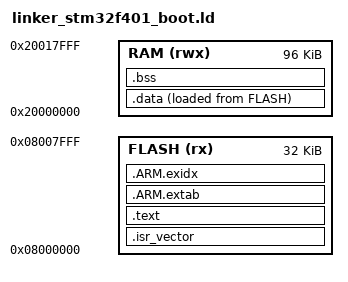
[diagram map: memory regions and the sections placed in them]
ENTRY(Reset_Handler)

MEMORY
{
    FLASH (rx)  : ORIGIN = 0x08000000, LENGTH = 32K
    RAM   (rwx) : ORIGIN = 0x20000000, LENGTH = 96K
}

_estack = ORIGIN(RAM) + LENGTH(RAM);

SECTIONS
{
    .isr_vector :
    {
        KEEP(*(.isr_vector))
        . = ALIGN(4);
    } > FLASH

    .text :
    {
        . = ALIGN(4);
        *(.text*)
        *(.rodata*)
        *(.glue_7)
        *(.glue_7t)
        *(.eh_frame*)
        . = ALIGN(4);
    } > FLASH

    .ARM.extab :
    {
        *(.ARM.extab*)
        . = ALIGN(4);
    } > FLASH

    .ARM.exidx :
    {
        *(.ARM.exidx*)
        . = ALIGN(4);
    } > FLASH

    .data :
    {
        . = ALIGN(4);
        _sdata = .;
        *(.data*)
        . = ALIGN(4);
        _edata = .;
    } > RAM AT > FLASH
    _sidata = LOADADDR(.data);

    .bss (NOLOAD) :
    {
        . = ALIGN(4);
        _sbss = .;
        *(.bss*)
        *(COMMON)
        . = ALIGN(4);
        _ebss = .;
    } > RAM

    /DISCARD/ :
    {
        *(.comment)
        *(.note*)
    }
}
